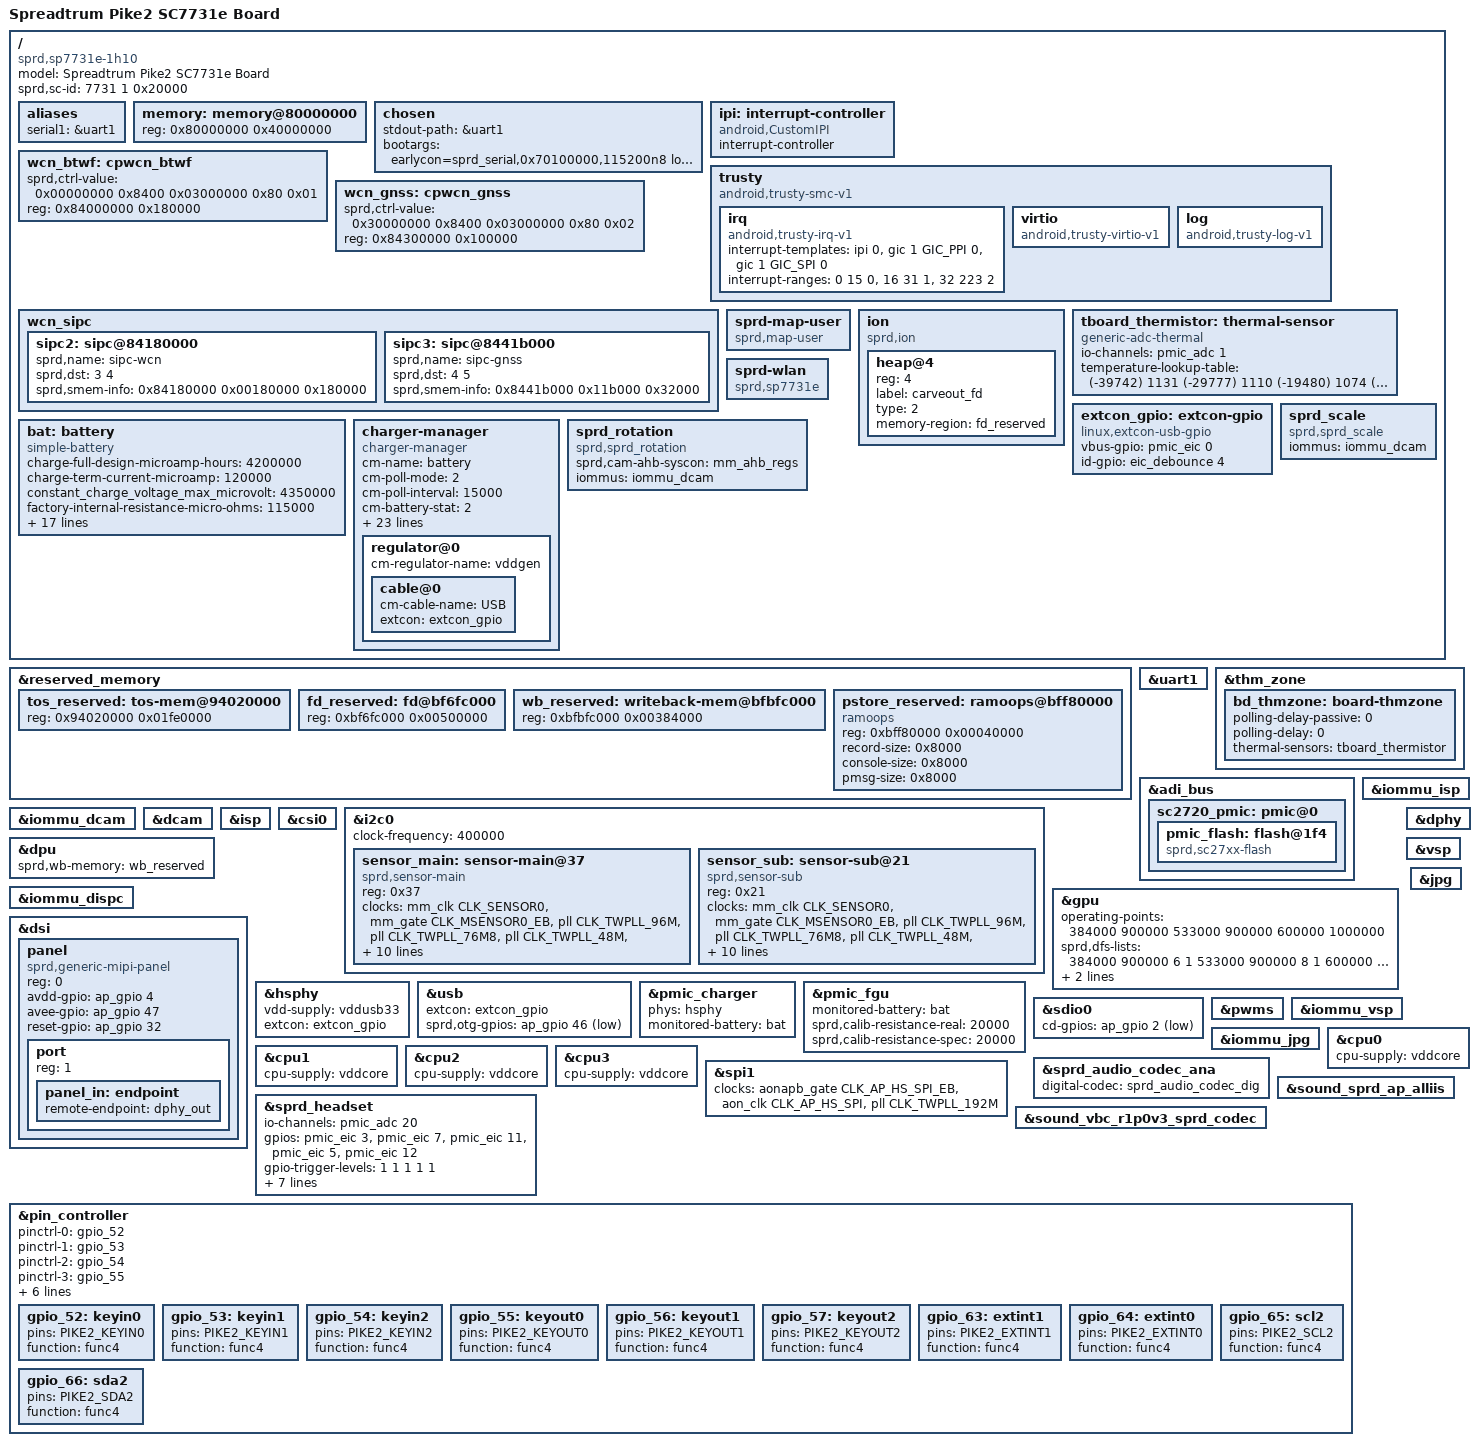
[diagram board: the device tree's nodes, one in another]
/*
 * Spreadtrum Pike2 SP7731e DTS file
 *
 * Copyright (C) 2019-2020, Spreadtrum Communications Inc.
 *
 * This file is licensed under a dual GPLv2 or X11 license.
 */

#include <dt-bindings/gpio/gpio.h>
#include "sc7731e.dtsi"
#include "sc7731e-wcn.dtsi"
#include "sc2720.dtsi"
#include "sprd-sound.dtsi"
#include "sp7731e-mach.dtsi"
#include "lcd/lcd_ili9881c_3lane_mipi_fhd.dtsi"
#include "lcd/lcd_7731e_fx_boe_ili9881c_mipi.dtsi"
#include "lcd/lcd_7731e_jd9364_qc_sat_mipi_hd.dtsi"
#include "lcd/lcd_sc7731e_qc_boe_jd9365da_mipi.dtsi"
#include "lcd/lcd_sc7731e_qc_jd9367_mipi.dtsi"
#include "lcd/lcd_7731e_hc_hsd_ili9881c_mipi.dtsi"
#include "lcd/lcd_7731e_hnh_boe_jd9366_mipi_hd.dtsi"
#include "lcd/lcd_sc7731e_ek79007_boe_2lane_mipi_wvga.dtsi"

/ {
	model = "Spreadtrum Pike2 SC7731e Board";

	compatible = "sprd,sp7731e-1h10", "sprd,sc7731e";

	sprd,sc-id = <7731 1 0x20000>;

	aliases {
		serial1 = &uart1;
	};

	memory: memory@80000000 {
		device_type = "memory";
		reg = <0x80000000 0x40000000>;
	};


	chosen {
		stdout-path = &uart1;
		bootargs = "earlycon=sprd_serial,0x70100000,115200n8 loglevel=1 console=ttyS1,115200n8 init=/init root=/dev/ram0 rw androidboot.hardware=sp7731e_1h10 androidboot.dtbo_idx=0 printk.devkmsg=on androidboot.boot_devices=soc/soc:ap-ahb/20600000.sdio";
	};

	ipi: interrupt-controller {
		compatible = "android,CustomIPI";
		#interrupt-cells = <1>;
		interrupt-controller;
	};

	trusty {
		compatible = "android,trusty-smc-v1";

		irq {
			compatible = "android,trusty-irq-v1";
			interrupt-templates = <&ipi 0>,
						<&gic 1 GIC_PPI 0>,
						<&gic 1 GIC_SPI 0>;
			interrupt-ranges = < 0  15 0>,
						<16  31 1>,
						<32 223 2>;
		};

		virtio {
			compatible = "android,trusty-virtio-v1";
		};

		log {
			compatible = "android,trusty-log-v1";
		};
	};
	/* WCN BASE mem adjust */
	wcn_btwf: cpwcn_btwf {
		sprd,ctrl-value = <0x00000000 0x8400 0x03000000
				   0x80 0x01>;
		reg = <0x84000000 0x180000>;
	};

	wcn_gnss: cpwcn_gnss {
		sprd,ctrl-value = <0x30000000 0x8400 0x03000000
				   0x80 0x02>;
		reg = <0x84300000 0x100000>;
	};

	wcn_sipc {
		/delete-node/ sipc@88180000;
		/delete-node/ sipc@8841b000;
		sipc2: sipc@84180000 {
		sprd,name = "sipc-wcn";
		sprd,dst = <3 4>; /* <dst core-id> */
		/* <ap-addr dst-maped-addr size> */
		sprd,smem-info = <0x84180000 0x00180000 0x180000>;
		};

		sipc3: sipc@8441b000 {
		sprd,name = "sipc-gnss";
		sprd,dst = <4 5>; /* <dst core-id> */
		/* <ap-addr dst-maped-addr size> */
		sprd,smem-info = <0x8441b000 0x11b000 0x32000>;
		};
	};

	sprd-map-user {
		compatible = "sprd,map-user";
	};

	ion {
		compatible = "sprd,ion";
		#address-cells = <1>;
		#size-cells = <0>;

		heap@4 {
			reg = <4>;
			label = "carveout_fd";
			type = <2>;
			memory-region = <&fd_reserved>;
		};
	};

	tboard_thermistor:thermal-sensor {
		compatible = "generic-adc-thermal";
		#thermal-sensor-cells = <0>;
		io-channels = <&pmic_adc 1>;
		io-channel-names = "sensor-channel";
		temperature-lookup-table = <	(-39742) 1131
						(-29777) 1110
						(-19480) 1074
						(-4679) 983
						10110 838
						24805 654
						44922 413
						54903 316
						64895 238
						74884 178
						84883 133
						94883 100
						104880 75
						114889 57
						124872 43 >;
	};

	extcon_gpio: extcon-gpio {
		compatible = "linux,extcon-usb-gpio";
		vbus-gpio = <&pmic_eic 0 GPIO_ACTIVE_HIGH>;
		id-gpio = <&eic_debounce 4 GPIO_ACTIVE_HIGH>;
	};

	bat: battery {
		compatible = "simple-battery";
		charge-full-design-microamp-hours = <4200000>;
		charge-term-current-microamp = <120000>;
		constant_charge_voltage_max_microvolt = <4350000>;
		factory-internal-resistance-micro-ohms = <115000>;
		voltage-min-design-microvolt = <3400000>;
		ocv-capacity-celsius = <20>;
		ocv-capacity-table-0 = <4320000 100>, <4258000 95>, <4199000 90>,
					<4144000 85>, <4091000 80>, <4045000 75>,
					<3988000 70>, <3954000 65>, <3911000 60>,
					<3868000 55>, <3833000 50>, <3810000 45>,
					<3794000 40>, <3781000 35>, <3772000 30>,
					<3760000 25>, <3732000 20>, <3705000 15>,
					<3668000 10>, <3614000 5>, <3450000 0>;
/*		voltage-temp-table = <1242000 750>, <1132000 800>, <1022000 850>, 
				      <886000 900>,  <803000 950>, <691000 1000>, 
				      <608000 1050>, <512000 1100>, <448000 1150>, 
				      <376000 1200>, <325000 1250>, <278000 1300>, 
				      <237000 1350>, <203000 1400>, <175000 1450>,
				      <148000 1500>, <128000 1550>, <118000 1600>;  */
		capacity-temp-table = <25 100>, <10 97>, <(-10) 60>;
		resistance-temp-table = <20 100>, <10 243>, <(-10) 468>;
		charge-sdp-current-microamp = <1100000 1500000>;
		charge-dcp-current-microamp = <1200000 1500000>;
		charge-cdp-current-microamp = <1200000 1500000>;
		charge-unknown-current-microamp = <1100000 1500000>;
	};

	charger-manager {
		compatible = "charger-manager";
		cm-name = "battery";
		cm-poll-mode = <2>;
		cm-poll-interval = <15000>;
		cm-battery-stat = <2>;

		cm-fullbatt-vchkdrop-ms = <30000>;
		cm-fullbatt-vchkdrop-volt = <60000>;
		cm-fullbatt-voltage = <4330000>;
		cm-fullbatt-current = <150000>;
		cm-fullbatt-capacity = <100>;

		cm-num-chargers = <1>;
		cm-chargers = "sc2720_charger";
		cm-fuel-gauge = "sc27xx-fgu";

		/* in deci centigrade */
		cm-battery-cold = <200>;
		cm-battery-cold-in-minus;
		cm-battery-hot = <800>;
		cm-battery-temp-diff = <100>;

		/* Allow charging for 6hr */
		cm-charging-max = <18000000>;
		/* recovery charging after stop charging 45min */
		cm-discharging-max = <2700000>;

		/* drop voltage in microVolts to allow shutdown */
		cm-shutdown-voltage = <3100000>;

		/* when 99% of the time is exceeded, it will be forced to 100% */
		cm-tickle-time-out = <500>;

		/* how much time to allow capacity change */
		cm-one-cap-time = <30>;

		/* when the safe charging voltage is exceeded, stop charging */
		cm-charge-voltage-max = <6500000>;
		/* drop voltage in microVolts to restart charging */
		cm-charge-voltage-drop = <700000>;
		cm-jeita-temp-table = <1000 1030 0 4360000>, <1150 1180 1200000 4360000>,
				<1450 1420 1500000 4360000>, <1600 1570 0 4360000>;
		regulator@0 {
			cm-regulator-name = "vddgen";
			cable@0 {
				cm-cable-name = "USB";
				extcon = <&extcon_gpio>;
			};
		};
	};

	sprd-wlan {
		compatible = "sprd,sp7731e";
	};

	sprd_scale {
		compatible = "sprd,sprd_scale";
		iommus = <&iommu_dcam>;
		status = "okay";
	};

	sprd_rotation {
		compatible = "sprd,sprd_rotation";
		sprd,cam-ahb-syscon = <&mm_ahb_regs>;
		iommus = <&iommu_dcam>;
		status = "okay";
	};
};

&reserved_memory {
	tos_reserved: tos-mem@94020000 {
		reg = <0x94020000 0x01fe0000>;
	};

	fd_reserved: fd@bf6fc000 {
		reg = <0xbf6fc000 0x00500000>;
	};

	wb_reserved: writeback-mem@bfbfc000 {
		reg = <0xbfbfc000 0x00384000>;
	};

	pstore_reserved: ramoops@bff80000 {
		compatible = "ramoops";
		reg = <0xbff80000 0x00040000>;
		record-size = <0x8000>;
		console-size = <0x8000>;
		pmsg-size = <0x8000>;
	};
};

&uart1 {
	status = "okay";
};

&thm_zone {
	bd_thmzone: board-thmzone {
		polling-delay-passive = <0>;
		polling-delay = <0>;
		thermal-sensors = <&tboard_thermistor>;
	};
};

&adi_bus {
    sc2720_pmic: pmic@0 {
        pmic_flash: flash@1f4 {
		compatible = "sprd,sc27xx-flash","sprd,sc2720-flash";
            status = "okay";
        };
         };
};
&iommu_dcam {
	status = "okay";
};

&iommu_isp {
	status = "okay";
};

&dcam {
	status = "okay";
};

&isp {
	status = "okay";
};

&csi0 {
	status = "okay";
};

&i2c0 {
	status = "okay";
	clock-frequency = <400000>;
	sensor_main: sensor-main@37 {
		compatible = "sprd,sensor-main";
		reg = <0x37>;
		clock-names = "clk_src", "sensor_eb",
			"clk_96m", "clk_76m8",
			"clk_48m", "clk_26m";
		clocks  = <&mm_clk CLK_SENSOR0>,
			<&mm_gate CLK_MSENSOR0_EB>,
			<&pll CLK_TWPLL_96M>,
			<&pll CLK_TWPLL_76M8>,
			<&pll CLK_TWPLL_48M>,
			<&ext_26m>;
		vddio-supply = <&vddcamio>;
		vddcama-supply = <&vddcama>;
		vddcamd-supply = <&vddcamd>;
		vddcammot-supply = <&vddcammot>;
		reset-gpios = <&ap_gpio 37 0>;
		power-down-gpios = <&ap_gpio 38 0>;
		host = "dcam0";
		sprd,phyid = <0>;
		csi = <&csi0>;
	};

	sensor_sub: sensor-sub@21 {
		compatible = "sprd,sensor-sub";
		reg = <0x21>;
		clock-names = "clk_src","sensor_eb",
			"clk_96m", "clk_76m8",
			"clk_48m", "clk_26m";
		clocks = <&mm_clk CLK_SENSOR0>,
			<&mm_gate CLK_MSENSOR0_EB>,
			<&pll CLK_TWPLL_96M>,
			<&pll CLK_TWPLL_76M8>,
			<&pll CLK_TWPLL_48M>,
			<&ext_26m>;
		vddio-supply = <&vddcamio>;
		vddcama-supply = <&vddcama>;
		vddcamd-supply = <&vddcamd>;
		vddcammot-supply = <&vddcammot>;
		reset-gpios = <&ap_gpio 37 0>;
		power-down-gpios = <&ap_gpio 39 0>;
		host = "dcam0";
		sprd,phyid = <0>;
		csi = <&csi0>;
	};
};

&gpu {
	operating-points = <
		/* kHz    uV */
		384000    900000
		533000    900000
		600000    1000000
		>;

	sprd,dfs-lists = <
		/* kHz  uV      idx div */
		384000  900000   6    1
		533000  900000   8    1
		600000  1000000  8    1
		>;

	sprd,dfs-scene-extreme = <2>;
	sprd,dfs-range-max = <2>;
};

&dpu {
	status = "okay";
	sprd,wb-memory = <&wb_reserved>;
};

&iommu_dispc {
	status = "okay";
};

&dsi {
	status = "okay";
	#address-cells = <1>;
	#size-cells = <0>;

	panel: panel {
		compatible = "sprd,generic-mipi-panel";
		#address-cells = <1>;
		#size-cells = <0>;
		reg = <0>;

		avdd-gpio = <&ap_gpio 4 GPIO_ACTIVE_HIGH>;
		avee-gpio = <&ap_gpio 47 GPIO_ACTIVE_HIGH>;
		reset-gpio = <&ap_gpio 32 GPIO_ACTIVE_HIGH>;
		port {
			reg = <1>;
			panel_in: endpoint {
				remote-endpoint = <&dphy_out>;
			};
		};
	};
};

&dphy {
	status = "okay";
};

&hsphy {
	vdd-supply = <&vddusb33>;
	extcon = <&extcon_gpio>;
};

&usb {
	extcon = <&extcon_gpio>;
	sprd,otg-gpios = <&ap_gpio 46 GPIO_ACTIVE_LOW>;
};

&pmic_charger {
	status = "okay";
	phys = <&hsphy>;
	monitored-battery = <&bat>;
};

&pmic_fgu {
	monitored-battery = <&bat>;
	sprd,calib-resistance-real = <20000>;
	sprd,calib-resistance-spec = <20000>;
};

&sdio0 {
	cd-gpios = <&ap_gpio 2 1>;
};

&pwms {
	status = "okay";
};

&vsp {
	status = "okay";
};

&iommu_vsp {
	status = "okay";
};

&jpg {
	status = "okay";
};

&iommu_jpg {
	status = "okay";
};

&cpu0 {
	cpu-supply = <&vddcore>;
};

&cpu1 {
	cpu-supply = <&vddcore>;
};

&cpu2 {
	cpu-supply = <&vddcore>;
};

&cpu3 {
	cpu-supply = <&vddcore>;
};

&spi1 {
	/*used for fingerprint sensor*/
	clock-names ="enable", "spi", "source";
	clocks = <&aonapb_gate CLK_AP_HS_SPI_EB>,
		<&aon_clk CLK_AP_HS_SPI>, <&pll CLK_TWPLL_192M>;
	status = "okay";
};



&sprd_audio_codec_ana {
	status = "okay";
	digital-codec = <&sprd_audio_codec_dig>;
};

&sprd_headset {
	status = "okay";
	io-channels = <&pmic_adc 20>;
	io-channel-names = "headmic_in_little";
	gpios = <&pmic_eic 3 GPIO_ACTIVE_HIGH>, <&pmic_eic 7 GPIO_ACTIVE_HIGH>,
		<&pmic_eic 11 GPIO_ACTIVE_HIGH>, <&pmic_eic 5 GPIO_ACTIVE_HIGH>,
		<&pmic_eic 12 GPIO_ACTIVE_HIGH>;
	gpio-trigger-levels = <1 1 1 1 1>;
	gpio-dbnc-intervals = <30 100 100 100 100>;
	gpio-names = "button", "detect_l",
		"detect_h", "detect_mic",
		"detect_all";
	adc-threshold-3pole-detect = <2950>;
	sprd,adc-gnd = <450>;
	sprd,stable-value = <2170>;
	sprd,coefficient = <917280>;
};

&sound_vbc_r1p0v3_sprd_codec {
	status = "okay";
};

&sound_sprd_ap_alliis {
	status = "okay";
};

&pin_controller {
	pinctrl-names =
	/* keyin0 ~ keyin2 */
	"gpio_52", "gpio_53", "gpio_54",
	/* keyout0 ~ keyout2 */
	"gpio_55", "gpio_56", "gpio_57",
	/* extint1, extint0, scl2, sda2 */
	"gpio_63", "gpio_64", "gpio_65", "gpio_66";
	pinctrl-0 = <&gpio_52>;
	pinctrl-1 = <&gpio_53>;
	pinctrl-2 = <&gpio_54>;
	pinctrl-3 = <&gpio_55>;
	pinctrl-4 = <&gpio_56>;
	pinctrl-5 = <&gpio_57>;
	pinctrl-6 = <&gpio_63>;
	pinctrl-7 = <&gpio_64>;
	pinctrl-8 = <&gpio_65>;
	pinctrl-9 = <&gpio_66>;

	gpio_52: keyin0 {
		pins = "PIKE2_KEYIN0";
		function = "func4";
	};

	gpio_53: keyin1 {
		pins = "PIKE2_KEYIN1";
		function = "func4";
	};

	gpio_54: keyin2 {
		pins = "PIKE2_KEYIN2";
		function = "func4";
	};

	gpio_55: keyout0 {
		pins = "PIKE2_KEYOUT0";
		function = "func4";
	};

	gpio_56: keyout1 {
		pins = "PIKE2_KEYOUT1";
		function = "func4";
	};

	gpio_57: keyout2 {
		pins = "PIKE2_KEYOUT2";
		function = "func4";
	};

	gpio_63: extint1 {
		pins = "PIKE2_EXTINT1";
		function = "func4";
	};

	gpio_64: extint0 {
		pins = "PIKE2_EXTINT0";
		function = "func4";
	};

	gpio_65: scl2 {
		pins = "PIKE2_SCL2";
		function = "func4";
	};

	gpio_66: sda2 {
		pins = "PIKE2_SDA2";
		function = "func4";
	};
};
